# C2000_Enhanced_Debug_HWBP_Registers register map
Vendor: Texas Instruments
Peripheral module from a debugger description file (folder C2000).
Address unit: 16 bits
Registers are 16-bit, access not given, no defined reset value unless marked. A register's access mark holds for its fields unless they carry their own. Offsets are as the file gives them; lines under a group give offsets from that group; [hi:lo] are bit positions; {n}, {i} and the like mark numbered series; 'fields as' and 'values as' point back to an identical list; <NAME> marks a mode.

## EnhancedDebugHWBPRegs — Enhanced Debug HWBP Registers
0x00 HWBP_MASK_LOW1 — Lower 16 bits of the Address mask register
0x01 HWBP_MASK_HIGH1 — Higher 16 bits of the Address mask register
0x02 HWBP_REF_LOW1 — Lower 16 bits of the Address reference register
0x03 HWBP_REF_HIGH1 — Higher 16 bits of the Address reference register
0x04 HWBP_CLEAR1 rw reset 0x0 — Hardware breakpoint clear register
  [0] EVENT_CLR — Event Clear register
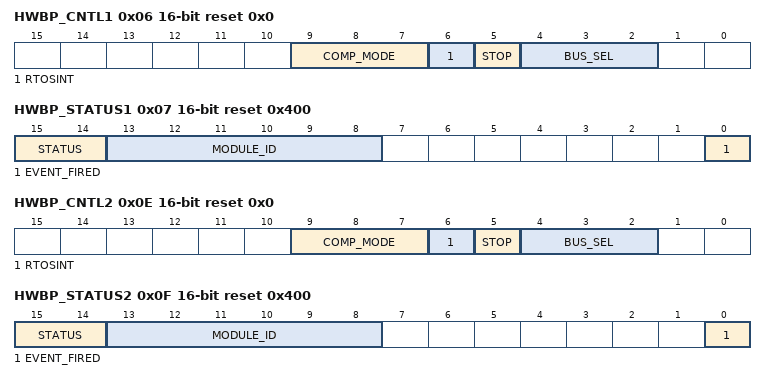
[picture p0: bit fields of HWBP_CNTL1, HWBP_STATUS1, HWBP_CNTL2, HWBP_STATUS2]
0x06 HWBP_CNTL1 rw reset 0x0 — Hardware breakpoint control register
  [9:7] COMP_MODE — Compare mode
  [6] RTOSINT — RTOSINT bit
  [5] STOP — Stop bit (Halt/No Halt of CPU)
  [4:2] BUS_SEL — Bus select bits
0x07 HWBP_STATUS1 ro reset 0x400 — Hardware breakpoint control register
  [15:14] STATUS — Status bits
  [13:8] MODULE_ID — Identification bits
  [0] EVENT_FIRED — HWBP Event Fired bits
0x08 HWBP_MASK_LOW2 — Lower 16 bits of the Address mask register
0x09 HWBP_MASK_HIGH2 — Higher 16 bits of the Address mask register
0x0A HWBP_REF_LOW2 — Lower 16 bits of the Address reference register
0x0B HWBP_REF_HIGH2 — Higher 16 bits of the Address reference register
0x0C HWBP_CLEAR2 rw reset 0x0 — Hardware breakpoint clear register
  [0] EVENT_CLR — Event Clear register
0x0E HWBP_CNTL2 rw reset 0x0 — Hardware breakpoint control register
  fields as HWBP_CNTL1
0x0F HWBP_STATUS2 ro reset 0x400 — Hardware breakpoint control register
  fields as HWBP_STATUS1
0x10 HWBP_MASK_LOW3 — Lower 16 bits of the Address mask register
0x11 HWBP_MASK_HIGH3 — Higher 16 bits of the Address mask register
0x12 HWBP_REF_LOW3 — Lower 16 bits of the Address reference register
0x13 HWBP_REF_HIGH3 — Higher 16 bits of the Address reference register
0x14 HWBP_CLEAR3 rw reset 0x0 — Hardware breakpoint clear register
  [0] EVENT_CLR — Event Clear register
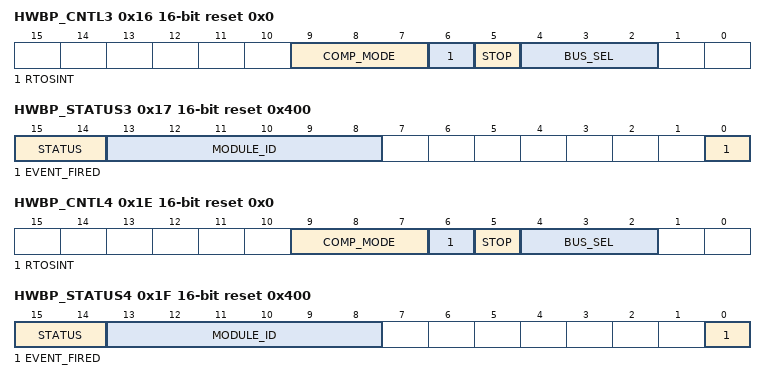
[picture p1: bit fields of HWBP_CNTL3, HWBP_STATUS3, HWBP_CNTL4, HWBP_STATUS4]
0x16 HWBP_CNTL3 rw reset 0x0 — Hardware breakpoint control register
  fields as HWBP_CNTL1
0x17 HWBP_STATUS3 ro reset 0x400 — Hardware breakpoint control register
  fields as HWBP_STATUS1
0x18 HWBP_MASK_LOW4 — Lower 16 bits of the Address mask register
0x19 HWBP_MASK_HIGH4 — Higher 16 bits of the Address mask register
0x1A HWBP_REF_LOW4 — Lower 16 bits of the Address reference register
0x1B HWBP_REF_HIGH4 — Higher 16 bits of the Address reference register
0x1C HWBP_CLEAR4 rw reset 0x0 — Hardware breakpoint clear register
  [0] EVENT_CLR — Event Clear register
0x1E HWBP_CNTL4 rw reset 0x0 — Hardware breakpoint control register
  fields as HWBP_CNTL1
0x1F HWBP_STATUS4 ro reset 0x400 — Hardware breakpoint control register
  fields as HWBP_STATUS1
0x20 HWBP_MASK_LOW5 — Lower 16 bits of the Address mask register
0x21 HWBP_MASK_HIGH5 — Higher 16 bits of the Address mask register
0x22 HWBP_REF_LOW5 — Lower 16 bits of the Address reference register
0x23 HWBP_REF_HIGH5 — Higher 16 bits of the Address reference register
0x24 HWBP_CLEAR5 rw reset 0x0 — Hardware breakpoint clear register
  [0] EVENT_CLR — Event Clear register
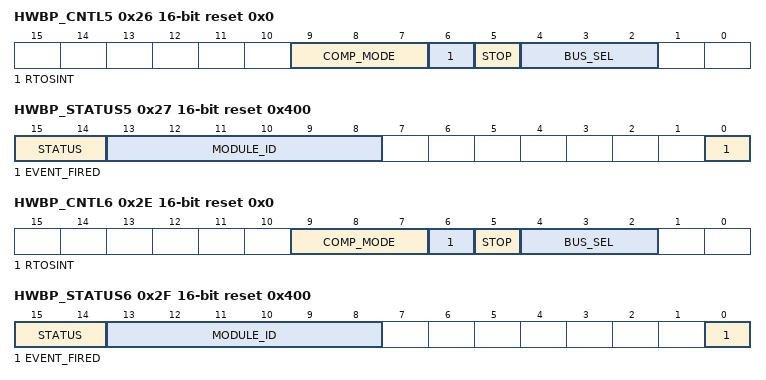
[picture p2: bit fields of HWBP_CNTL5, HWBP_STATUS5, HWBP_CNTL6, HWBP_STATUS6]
0x26 HWBP_CNTL5 rw reset 0x0 — Hardware breakpoint control register
  fields as HWBP_CNTL1
0x27 HWBP_STATUS5 ro reset 0x400 — Hardware breakpoint control register
  fields as HWBP_STATUS1
0x28 HWBP_MASK_LOW6 — Lower 16 bits of the Address mask register
0x29 HWBP_MASK_HIGH6 — Higher 16 bits of the Address mask register
0x2A HWBP_REF_LOW6 — Lower 16 bits of the Address reference register
0x2B HWBP_REF_HIGH6 — Higher 16 bits of the Address reference register
0x2C HWBP_CLEAR6 rw reset 0x0 — Hardware breakpoint clear register
  [0] EVENT_CLR — Event Clear register
0x2E HWBP_CNTL6 rw reset 0x0 — Hardware breakpoint control register
  fields as HWBP_CNTL1
0x2F HWBP_STATUS6 ro reset 0x400 — Hardware breakpoint control register
  fields as HWBP_STATUS1
0x30 HWBP_MASK_LOW7 — Lower 16 bits of the Address mask register
0x31 HWBP_MASK_HIGH7 — Higher 16 bits of the Address mask register
0x32 HWBP_REF_LOW7 — Lower 16 bits of the Address reference register
0x33 HWBP_REF_HIGH7 — Higher 16 bits of the Address reference register
0x34 HWBP_CLEAR7 rw reset 0x0 — Hardware breakpoint clear register
  [0] EVENT_CLR — Event Clear register
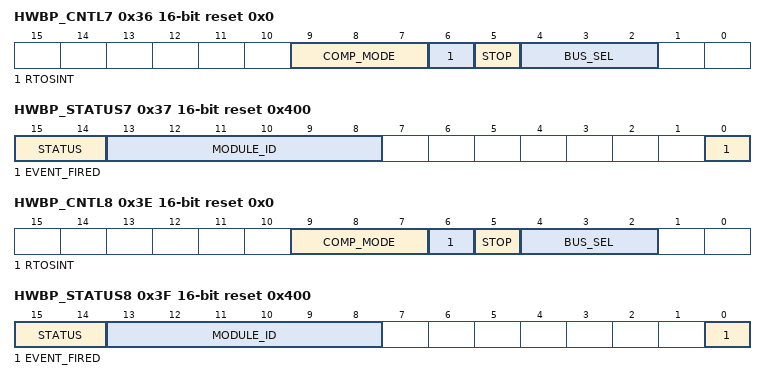
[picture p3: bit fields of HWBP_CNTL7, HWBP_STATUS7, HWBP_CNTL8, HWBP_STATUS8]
0x36 HWBP_CNTL7 rw reset 0x0 — Hardware breakpoint control register
  fields as HWBP_CNTL1
0x37 HWBP_STATUS7 ro reset 0x400 — Hardware breakpoint control register
  fields as HWBP_STATUS1
0x38 HWBP_MASK_LOW8 — Lower 16 bits of the Address mask register
0x39 HWBP_MASK_HIGH8 — Higher 16 bits of the Address mask register
0x3A HWBP_REF_LOW8 — Lower 16 bits of the Address reference register
0x3B HWBP_REF_HIGH8 — Higher 16 bits of the Address reference register
0x3C HWBP_CLEAR8 rw reset 0x0 — Hardware breakpoint clear register
  [0] EVENT_CLR — Event Clear register
0x3E HWBP_CNTL8 rw reset 0x0 — Hardware breakpoint control register
  fields as HWBP_CNTL1
0x3F HWBP_STATUS8 ro reset 0x400 — Hardware breakpoint control register
  fields as HWBP_STATUS1
